AUTOSAR XML (schema 4-0-3)
package /WipM
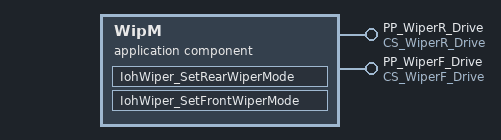
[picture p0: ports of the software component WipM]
  application sw component type WipM
    provide port PP_WiperR_Drive: provided-interface=CS_WiperR_Drive
    provide port PP_WiperF_Drive: provided-interface=CS_WiperF_Drive
    behavior IB_WipM: handle-termination-and-restart=NO-SUPPORT
      operation invoked event OIE_WiperR_Drive: start-on-event=IohWiper_SetRearWiperMode, operation=PP_WiperR_Drive.OP_SET
      operation invoked event OIE_WiperF_Drive: start-on-event=IohWiper_SetFrontWiperMode, operation=PP_WiperF_Drive.OP_SET
      runnable IohWiper_SetRearWiperMode: can-be-invoked-concurrently=true
      runnable IohWiper_SetFrontWiperMode: can-be-invoked-concurrently=true
package /RootP_Implementation
  swc implementation Implementation_WipM: programming-language=C, sw-version=1.0.0, vendor-id=1, behavior=IB_WipM
    code-descriptors:
      code SRC: artifact-descriptors=autosar-engineering-object={short-label=EngObject, category=SWSRC}
    resource consumption Resources
